# CY8C5888LTI_LP097 register map
File version: 0.1
CY8C58LP
Registers are 8-bit, read-write, no defined reset value unless marked. A register's access mark holds for its fields unless they carry their own. Offsets are from the block's base; lines under a group give offsets from that group; [hi:lo] are bit positions; {n}, {i} and the like mark numbered series; 'fields as' and 'values as' point back to an identical list; <NAME> marks a mode.

## Memory map
0x00000000 USBFS
0x00000000 Droop_Filter
0x00000000 SystemTickTimer
0x00000000 I2C_Master
0x40006462 I2S
0x40006468 PDM_CIC_Status_Reg
0x4000647A PDM_CIC_Int_Ctrl_Reg

## USBFS
Base 0x00000000
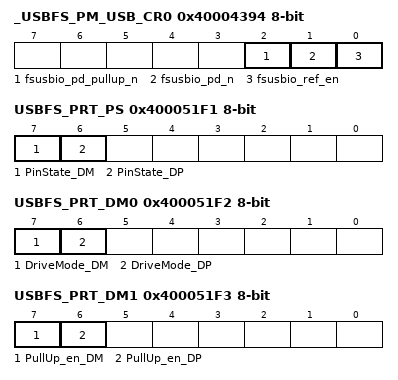
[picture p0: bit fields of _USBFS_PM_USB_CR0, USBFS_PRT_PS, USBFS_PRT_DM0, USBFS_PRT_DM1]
0x40004394 _USBFS_PM_USB_CR0 — USB Power Mode Control Register 0
  [2] fsusbio_pd_pullup_n, [1] fsusbio_pd_n, [0] fsusbio_ref_en
0x400043A5 USBFS_PM_ACT_CFG — Active Power Mode Configuration Register
0x400043B5 USBFS_PM_STBY_CFG — Standby Power Mode Configuration Register
0x400051F1 USBFS_PRT_PS — Port Pin State Register
  [7] PinState_DM ro, [6] PinState_DP ro
0x400051F2 USBFS_PRT_DM0 — Port Drive Mode Register
  [7] DriveMode_DM, [6] DriveMode_DP
0x400051F3 USBFS_PRT_DM1 — Port Drive Mode Register
  [7] PullUp_en_DM, [6] PullUp_en_DP
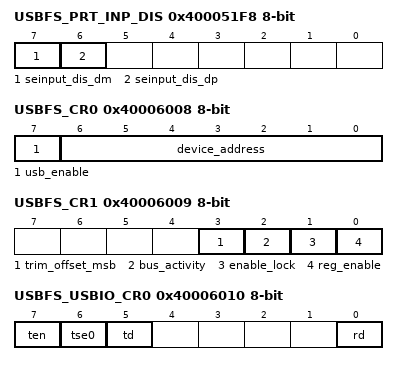
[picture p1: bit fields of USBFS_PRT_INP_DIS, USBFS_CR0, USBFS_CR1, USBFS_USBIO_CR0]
0x400051F8 USBFS_PRT_INP_DIS — Input buffer disable override
  [7] seinput_dis_dm, [6] seinput_dis_dp
0x40006000 USBFS_EP0_DR0 — bmRequestType
0x40006001 USBFS_EP0_DR1 — bRequest
0x40006002 USBFS_EP0_DR2 — wValueLo
0x40006003 USBFS_EP0_DR3 — wValueHi
0x40006004 USBFS_EP0_DR4 — wIndexLo
0x40006005 USBFS_EP0_DR5 — wIndexHi
0x40006006 USBFS_EP0_DR6 — lengthLo
0x40006007 USBFS_EP0_DR7 — lengthHi
0x40006008 USBFS_CR0 — USB Control Register 0
  [7] usb_enable, [6:0] device_address ro
0x40006009 USBFS_CR1 — USB Control Register 1
  [3] trim_offset_msb, [2] bus_activity, [1] enable_lock, [0] reg_enable
{0x40005FFE+0x10*i} USBFS_SIE_EP{i}_CR0 (i=1..8) — The Endpoint{i} Control Register
0x40006010 USBFS_USBIO_CR0 — USBIO Control Register 0
  [7] ten, [6] tse0, [5] td, [0] rd ro
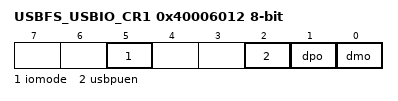
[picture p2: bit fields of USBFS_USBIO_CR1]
0x40006012 USBFS_USBIO_CR1 — USBIO Control Register 1
  [5] iomode, [2] usbpuen, [1] dpo ro, [0] dmo ro
0x4000608C USBFS_BUF_SIZE — Dedicated Endpoint Buffer Size Register
0x4000608E USBFS_EP_ACTIVE — Endpoint Active Indication Register
0x4000608F USBFS_EP_TYPE — Endpoint Type (IN/OUT) Indication
0x4000609D USBFS_USB_CLK_EN — USB Block Clock Enable Register

## PDM_CIC_Status_Reg
Base 0x40006468
0x00 PDM_CIC_Status_Reg_STATUS_REG
0x20 PDM_CIC_Status_Reg_MASK_REG
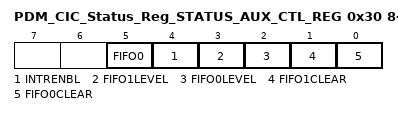
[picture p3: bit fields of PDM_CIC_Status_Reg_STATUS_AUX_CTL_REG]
0x30 PDM_CIC_Status_Reg_STATUS_AUX_CTL_REG
  [5] FIFO0 — FIFO0 clear
    1=ENABLED (Enable counter); 0=DISABLED (Disable counter)
  [4] INTRENBL — Enables or disables the Interrupt
    1=ENABLED (Interrupt enabled); 0=DISABLED (Interrupt disabled)
  [3] FIFO1LEVEL — FIFO level
    1=ENABLED (FIFO LVL: input mode: FIFO at least 1/2 empty; output mode: FIFO at least 1/2 full); 0=DISABLED (FIFO LVL: input mode: FIFO not full; output mode: FIFO not empty)
  [2] FIFO0LEVEL — FIFO level
    values as FIFO1LEVEL
  [1] FIFO1CLEAR — FIFO clear
    1=ENABLED (Clear FIFO state); 0=DISABLED (Normal FIFO operation)
  [0] FIFO0CLEAR — FIFO clear
    values as FIFO1CLEAR

## PDM_CIC_Int_Ctrl_Reg
Base 0x4000647A
0x00 PDM_CIC_Int_Ctrl_Reg_CONTROL_REG

## I2S
Base 0x40006462
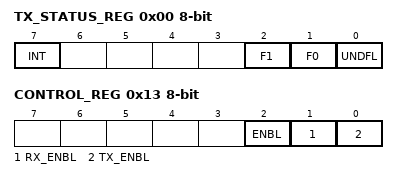
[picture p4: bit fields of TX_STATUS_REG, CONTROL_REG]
0x00 TX_STATUS_REG
  [7] INT ro — Interrupt bit
  [2] F1 ro — FIFO 1 state
    0=FULL; 1=NOT_FULL
  [1] F0 ro — FIFO 0 state
    0=FULL; 1=NOT_FULL
  [0] UNDFL ro — FIFO Underflow Error
    0=NO_UNDERFLOW; 1=UNDERFLOW
0x13 CONTROL_REG
  [all] fields
    1=ENABLED; 0=DISABLED
  [2] ENBL — Starts the generation of the WS and SCK outputs
  [1] RX_ENBL — Enables Rx direction. This bit is applicable only if Rx direction presents for the component
  [0] TX_ENBL — Enables Tx direction. This bit is applicable only if Tx direction presents for the component

## SystemTickTimer
Base 0x00000000
0x40004381 SystemTickTimer_CTW_INTERVAL_REG — Timewheel Configuration Register 1
  [3:0] ctw_interval — Sets the central timewheel interval.
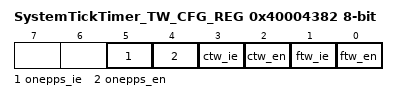
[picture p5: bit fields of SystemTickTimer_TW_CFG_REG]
0x40004382 SystemTickTimer_TW_CFG_REG — Timewheel Configuration Register 2
  [5] onepps_ie — When set and one pulse-per-second is enabled, an interrupt is issued when the pulse occurs.
    1=Enabled (One PPS interrupt is enabled); 0=Disabled (One PPS interrupt is disabled)
  [4] onepps_en — When set, the system returns to the active global power mode once every second.
    1=Enabled (One PPS is enabled); 0=Disabled (One PPS is disabled)
  [3] ctw_ie — When set and the central timewheel is enabled, an interrupt is issued when the central timewheel reaches the selected interval.
    1=Enabled (CTW interrupt is enabled); 0=Disabled (CTW interrupt is disabled)
  [2] ctw_en — When set, the system returns to the active global power mode when the central timewheel reaches the selected interval.
    1=Enabled (CTW is enabled); 0=Disabled (CTW is disabled)
  [1] ftw_ie — When set and the fast timewheel is enabled, an interrupt is issued when it reaches the terminal count.
    1=Enabled (FTW interrupt is enabled); 0=Disabled (FTW interrupt is disabled)
  [0] ftw_en — When set, the system returns to the active global power mode when the fast timewheel reaches the selected interval.
    1=Enabled (FTW is enabled); 0=Disabled (FTW is disabled)
